AUTOSAR XML (schema 4-2-2)
package /ARPackage
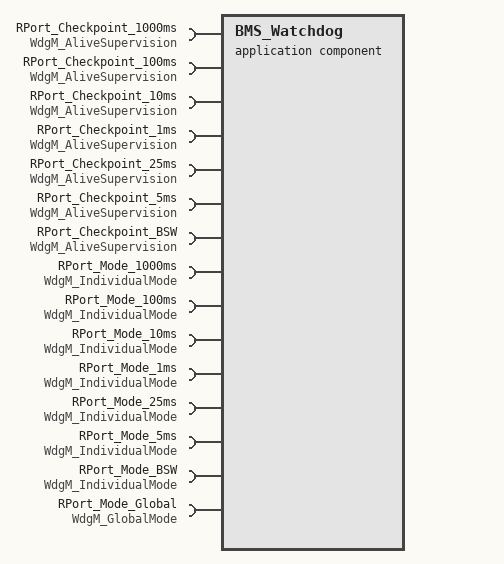
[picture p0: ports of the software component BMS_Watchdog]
  application sw component type BMS_Watchdog
    15 x require port:
      RPort_Checkpoint_1000ms: required-interface=WdgM_AliveSupervision
      RPort_Checkpoint_100ms: required-interface=WdgM_AliveSupervision
      RPort_Checkpoint_10ms: required-interface=WdgM_AliveSupervision
      RPort_Checkpoint_1ms: required-interface=WdgM_AliveSupervision
      RPort_Checkpoint_25ms: required-interface=WdgM_AliveSupervision
      RPort_Checkpoint_5ms: required-interface=WdgM_AliveSupervision
      RPort_Checkpoint_BSW: required-interface=WdgM_AliveSupervision
      RPort_Mode_1000ms: required-interface=WdgM_IndividualMode
      RPort_Mode_100ms: required-interface=WdgM_IndividualMode
      RPort_Mode_10ms: required-interface=WdgM_IndividualMode
      RPort_Mode_1ms: required-interface=WdgM_IndividualMode
      RPort_Mode_25ms: required-interface=WdgM_IndividualMode
      RPort_Mode_5ms: required-interface=WdgM_IndividualMode
      RPort_Mode_BSW: required-interface=WdgM_IndividualMode
      RPort_Mode_Global: required-interface=WdgM_GlobalMode
    behavior SwcInternalBehavior: data-type-mapping=WdgM_Type_Map
      8 x timing event:
        TimingEvent_1000ms: start-on-event=RE_WdgM_SE_1000ms, period=1.0
        TimingEvent_100ms: start-on-event=RE_WdgM_SE_100ms, period=0.1
        TimingEvent_10ms: start-on-event=RE_WdgM_SE_10ms, period=0.01
        TimingEvent_1ms: start-on-event=RE_WdgM_SE_1ms, period=0.001
        TimingEvent_25ms: start-on-event=RE_WdgM_SE_25ms, period=0.025
        TimingEvent_5ms: start-on-event=RE_WdgM_SE_5ms, period=0.005
        TimingEvent_BSW: start-on-event=RE_WdgM_SE_BSW, period=0.01
        TimingEvent_SystemProcess: start-on-event=RE_WdgM_SystemProcess, period=0.01
      8 x runnable:
        RE_WdgM_SE_1000ms
          sync call SynchronousServerCallPoint_0: operation=RPort_Checkpoint_1000ms.CheckpointReached
          sync call SynchronousServerCallPoint_1: operation=RPort_Checkpoint_1000ms.CheckpointReached
        RE_WdgM_SE_100ms
          sync call SynchronousServerCallPoint_0: operation=RPort_Checkpoint_100ms.CheckpointReached
          sync call SynchronousServerCallPoint_1: operation=RPort_Checkpoint_100ms.CheckpointReached
        RE_WdgM_SE_10ms
          sync call SynchronousServerCallPoint_0: operation=RPort_Checkpoint_10ms.CheckpointReached
          sync call SynchronousServerCallPoint_1: operation=RPort_Checkpoint_10ms.CheckpointReached
        RE_WdgM_SE_1ms
          sync call SynchronousServerCallPoint_0: operation=RPort_Checkpoint_1ms.CheckpointReached
          sync call SynchronousServerCallPoint_1: operation=RPort_Checkpoint_1ms.CheckpointReached
        RE_WdgM_SE_25ms
          sync call SynchronousServerCallPoint_0: operation=RPort_Checkpoint_25ms.CheckpointReached
          sync call SynchronousServerCallPoint_1: operation=RPort_Checkpoint_25ms.CheckpointReached
        RE_WdgM_SE_5ms
          sync call SynchronousServerCallPoint_0: operation=RPort_Checkpoint_5ms.CheckpointReached
          sync call SynchronousServerCallPoint_1: operation=RPort_Checkpoint_5ms.CheckpointReached
        RE_WdgM_SE_BSW
          sync call SynchronousServerCallPoint_0: operation=RPort_Checkpoint_BSW.CheckpointReached
          sync call SynchronousServerCallPoint_1: operation=RPort_Checkpoint_BSW.CheckpointReached
        RE_WdgM_SystemProcess
          mode-access-points:
            RPort_Mode_1ms.currentMode
            RPort_Mode_10ms.currentMode
            RPort_Mode_100ms.currentMode
            RPort_Mode_5ms.currentMode
            RPort_Mode_Global.currentMode
            RPort_Mode_1000ms.currentMode
            RPort_Mode_BSW.currentMode
            RPort_Mode_25ms.currentMode
